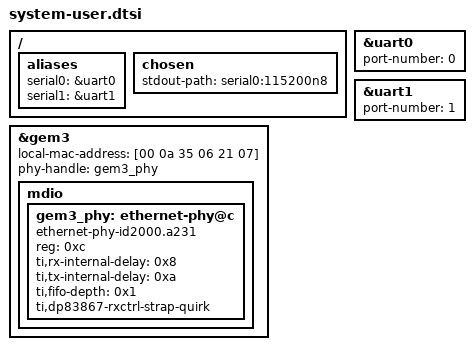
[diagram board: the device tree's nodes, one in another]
// SPDX-License-Identifier: MIT
// Copyright (C) 2025-2026, Opsero Electronic Design Inc.  All rights reserved.

/*
 * SoC-side board fixups for zcu106 (ZynqMP), layered on top of the
 * gen-machineconf / lopper-generated Linux device tree (which already carries
 * the PS config and the design's PL hardware from the XSA). Scoped to the Linux
 * domain by device-tree.bbappend. Ported from the Ethernet FMC Max AXI Ethernet PetaLinux BSP.
 */

/* 2025.2 gen-machineconf assigns port-number=0 to uart1, making ttyPS0 map
 * to uart1. Vitis bsp.yaml confirms this board uses psu_uart_0, so force
 * ttyPS0 back to uart0. */
&uart0 {
   port-number = <0>;
};
&uart1 {
   port-number = <1>;
};
/ {
   aliases {
      serial0 = &uart0;
      serial1 = &uart1;
   };
   chosen {
      stdout-path = "serial0:115200n8";
   };
};

/* PS GEM3 (board RJ45): the SDT flow does not describe the board-level
 * TI DP83867 PHY, so Linux falls back to the Generic PHY driver and the
 * RGMII clock delays are never programmed - the link negotiates 1G but
 * passes no packets. Values from the official zynqmp-zcu106-revA.dts
 * (PHY at MDIO address 0xc). The fixed MAC replaces the random one the
 * SDT flow leaves us with, keeping DHCP leases stable across boots.
 */
&gem3 {
	local-mac-address = [00 0a 35 06 21 07];
	phy-handle = <&gem3_phy>;
	mdio {
		#address-cells = <1>;
		#size-cells = <0>;
		gem3_phy: ethernet-phy@c {
			compatible = "ethernet-phy-id2000.a231";
			reg = <0xc>;
			ti,rx-internal-delay = <0x8>;
			ti,tx-internal-delay = <0xa>;
			ti,fifo-depth = <0x1>;
			ti,dp83867-rxctrl-strap-quirk;
		};
	};
};
